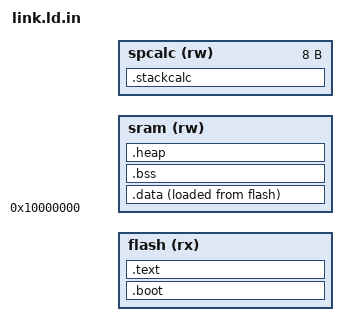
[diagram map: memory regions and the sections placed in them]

MEMORY 
{ 
  flash (rx) : ORIGIN = @SYSTEM_INSTR_MEMORY_START@, LENGTH = @SPI_FLASH_SIZE_BYTES@ - @USER_CODE_FLASH_OFFSET@
  sram  (rw) : ORIGIN = 0x10000000, LENGTH = @MAIN_MEMORY_SIZE_B@ - 8
  spcalc(rw) : ORIGIN = 0x10000000 + @MAIN_MEMORY_SIZE_B@ - 8, LENGTH = 8
}

ENTRY(__start)

SECTIONS
{
    .boot :
    {
        PROVIDE(_text_start = .);
        KEEP(*(.boot.*))	         /* boot code */
    } > flash

    .text :
    {
        . = ALIGN(4);
        *(.text .text.*)		 /* remaining code */
        . = ALIGN(4);
        PROVIDE(_text_end = .);
    } > flash

    .data (NOLOAD):
    {
        PROVIDE(__data_load__ = LOADADDR (.data));
        PROVIDE(_data_start = .);
        *(.rodata)			 /* read-only data (constants) */
        *(.rodata*)
        *(.rdata*)
        . = ALIGN (4);
        *(.got.plt) *(.got)
        *(.shdata)
        *(.data .data.* .gnu.linkonce.d.*)
        *(.ram)
        *(.eh_frame)
        . = ALIGN(4);
        PROVIDE(_data_end = .);
        PROVIDE(_edata = .);
    } > sram AT> flash

    .bss (NOLOAD):
    {
        . = ALIGN(4);
        PROVIDE(_bss_start = .);
        *(.bss*)
        *(COMMON)
        . = ALIGN(4);
        PROVIDE(_bss_end = .);
    } > sram

    .heap (NOLOAD):
    {
        __heap_start__ = .;
        end = __heap_start__;
        _end = end;
        __end = end;
        KEEP(*(*.heap))
        __heap_end__ = .;
        __HeapLimit = __heap_end__;
    } > sram

    .stackcalc (NOLOAD):
    {
        PROVIDE(_sp = .);
    } > spcalc
}
